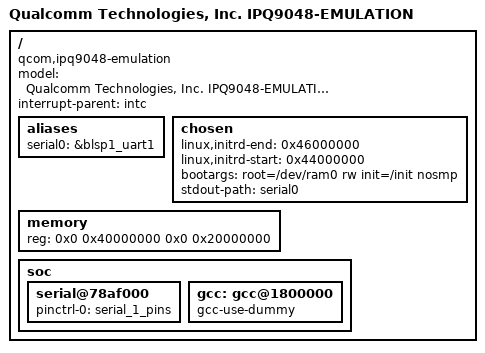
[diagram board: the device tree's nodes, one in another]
// SPDX-License-Identifier: (GPL-2.0+ OR BSD-3-Clause)
/*
 * IPQ9048 Emulation board device tree source
 *
 * Copyright (c) 2020 The Linux Foundation. All rights reserved.
 */

/dts-v1/;

#include "ipq9048.dtsi"

/ {
	#address-cells = <0x2>;
	#size-cells = <0x2>;
	model = "Qualcomm Technologies, Inc. IPQ9048-EMULATION";
	compatible = "qcom,ipq9048-emulation", "qcom,ipq9048";
	interrupt-parent = <&intc>;

	aliases {
		serial0 = &blsp1_uart1;
	};

	chosen {
		linux,initrd-end = <0x46000000>;
		linux,initrd-start = <0x44000000>;
		bootargs = "root=/dev/ram0 rw init=/init nosmp";
		stdout-path = "serial0";
	};

	memory {
		device_type = "memory";
		reg = <0x0 0x40000000 0x0 0x20000000>;
	};

	soc {
		serial@78af000 {
			pinctrl-0 = <&serial_1_pins>;
			pinctrl-names = "default";
			status = "ok";
		};

		gcc: gcc@1800000 {
			gcc-use-dummy;
		};
	};
};
